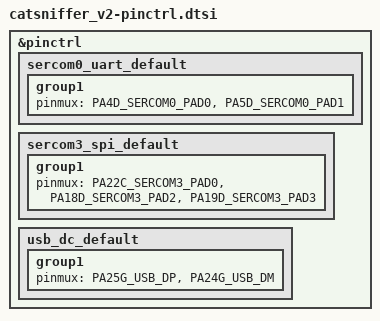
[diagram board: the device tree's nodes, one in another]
/*
 * Copyright (c) 2026 Electronic Cats
 * SPDX-License-Identifier: Apache-2.0
 *
 * CatSniffer v2 (ATSAMD21E17A/E17D) pinctrl configuration
 *
 * SERCOM0 UART  - CC1352P1 at 921600 baud
 *   TX = PA04 (function D -> SERCOM0 PAD0), txpo = 0
 *   RX = PA05 (function D -> SERCOM0 PAD1), rxpo = 1
 *
 * SERCOM3 SPI   - SX1262
 *   MISO = PA22 (function C -> SERCOM3 PAD0), DIPO = 0
 *   MOSI = PA18 (function D -> SERCOM3 PAD2), DOPO = 1
 *   SCK  = PA19 (function D -> SERCOM3 PAD3), DOPO = 1
 *   CS   = PA17 as GPIO (software CS, not in pinmux)
 *
 * USB           - native SAMD21 USB device controller
 *   D- = PA24 (function G -> USB_DM)
 *   D+ = PA25 (function G -> USB_DP)
 */

#include <dt-bindings/pinctrl/samd21-da1eXabcd-pinctrl.h>

&pinctrl {
	sercom0_uart_default: sercom0_uart_default {
		group1 {
			pinmux = <PA4D_SERCOM0_PAD0>,   /* TX */
				 <PA5D_SERCOM0_PAD1>;   /* RX */
		};
	};

	sercom3_spi_default: sercom3_spi_default {
		group1 {
			pinmux = <PA22C_SERCOM3_PAD0>,  /* MISO */
				 <PA18D_SERCOM3_PAD2>,  /* MOSI */
				 <PA19D_SERCOM3_PAD3>;  /* SCK  */
		};
	};

	usb_dc_default: usb_dc_default {
		group1 {
			pinmux = <PA25G_USB_DP>,
				 <PA24G_USB_DM>;
		};
	};
};
